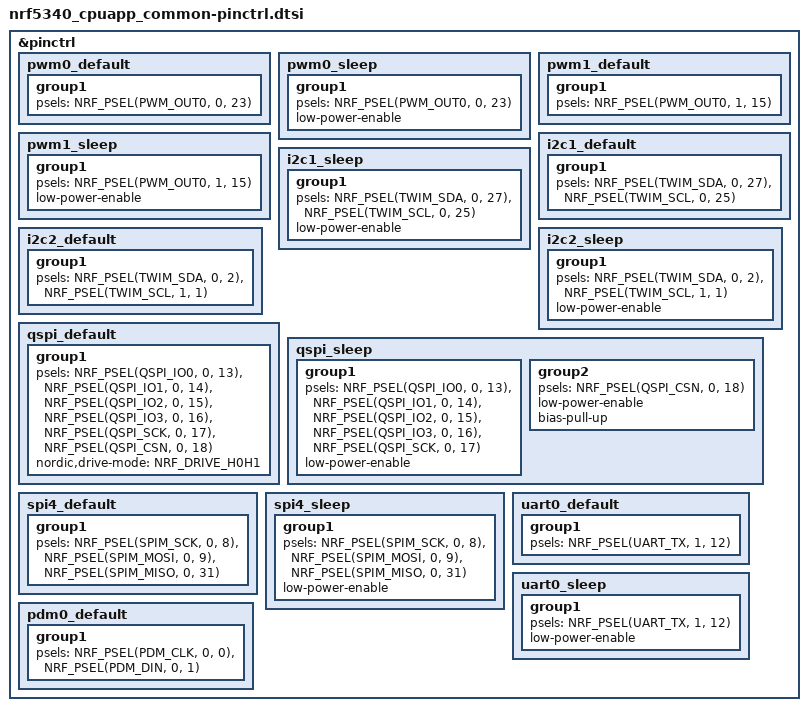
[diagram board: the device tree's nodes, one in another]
/*
 * Copyright (c) 2025 ZSWatch Project
 * SPDX-License-Identifier: Apache-2.0
 */

&pinctrl {
    pwm0_default: pwm0_default {
        group1 {
            psels = <NRF_PSEL(PWM_OUT0, 0, 23)>;
        };
    };

    pwm0_sleep: pwm0_sleep {
        group1 {
            psels = <NRF_PSEL(PWM_OUT0, 0, 23)>;
            low-power-enable;
        };
    };

    pwm1_default: pwm1_default {
        group1 {
            psels = <NRF_PSEL(PWM_OUT0, 1, 15)>;
        };
    };

    pwm1_sleep: pwm1_sleep {
        group1 {
            psels = <NRF_PSEL(PWM_OUT0, 1, 15)>;
            low-power-enable;
        };
    };

    i2c1_default: i2c1_default {
        group1 {
            psels = <NRF_PSEL(TWIM_SDA, 0, 27)>,
                    <NRF_PSEL(TWIM_SCL, 0, 25)>;
        };
    };

    i2c1_sleep: i2c1_sleep {
        group1 {
            psels = <NRF_PSEL(TWIM_SDA, 0, 27)>,
                    <NRF_PSEL(TWIM_SCL, 0, 25)>;
            low-power-enable;
        };
    };

    i2c2_default: i2c2_default {
        group1 {
            psels = <NRF_PSEL(TWIM_SDA, 0, 2)>,
                    <NRF_PSEL(TWIM_SCL, 1, 1)>;
        };
    };

    i2c2_sleep: i2c2_sleep {
        group1 {
            psels = <NRF_PSEL(TWIM_SDA, 0, 2)>,
                    <NRF_PSEL(TWIM_SCL, 1, 1)>;
            low-power-enable;
        };
    };

    qspi_default: qspi_default {
        group1 {
            psels = <NRF_PSEL(QSPI_IO0, 0, 13)>,
                    <NRF_PSEL(QSPI_IO1, 0, 14)>,
                    <NRF_PSEL(QSPI_IO2, 0, 15)>,
                    <NRF_PSEL(QSPI_IO3, 0, 16)>,
                    <NRF_PSEL(QSPI_SCK, 0, 17)>,
                    <NRF_PSEL(QSPI_CSN, 0, 18)>;
            nordic,drive-mode = <NRF_DRIVE_H0H1>;
        };
    };

    qspi_sleep: qspi_sleep {
        group1 {
            psels = <NRF_PSEL(QSPI_IO0, 0, 13)>,
                    <NRF_PSEL(QSPI_IO1, 0, 14)>,
                    <NRF_PSEL(QSPI_IO2, 0, 15)>,
                    <NRF_PSEL(QSPI_IO3, 0, 16)>,
                    <NRF_PSEL(QSPI_SCK, 0, 17)>;
            low-power-enable;
        };

        group2 {
            psels = <NRF_PSEL(QSPI_CSN, 0, 18)>;
            low-power-enable;
            bias-pull-up;
        };
    };

    spi4_default: spi4_default {
        group1 {
            psels = <NRF_PSEL(SPIM_SCK, 0, 8)>,
                    <NRF_PSEL(SPIM_MOSI, 0, 9)>,
                    <NRF_PSEL(SPIM_MISO, 0, 31)>; // TODO: Assigned to an unused pin. Test to remove it!
        };
    };

    spi4_sleep: spi4_sleep {
        group1 {
            psels = <NRF_PSEL(SPIM_SCK, 0, 8)>,
                    <NRF_PSEL(SPIM_MOSI, 0, 9)>,
                    <NRF_PSEL(SPIM_MISO, 0, 31)>; // TODO: Assigned to an unused pin. Test to remove it!
            low-power-enable;
        };
    };

    uart0_default: uart0_default {
        group1 {
            psels = <NRF_PSEL(UART_RX, 1, 11)>;
            psels = <NRF_PSEL(UART_TX, 1, 12)>;
        };
    };

    uart0_sleep: uart0_sleep {
        group1 {
            psels = <NRF_PSEL(UART_RX, 1, 11)>;
            psels = <NRF_PSEL(UART_TX, 1, 12)>;
            low-power-enable;
        };
    };

    pdm0_default: pdm0_default {
        group1 {
            psels = <NRF_PSEL(PDM_CLK, 0, 0)>,
                <NRF_PSEL(PDM_DIN, 0, 1)>;
        };
    };
};
